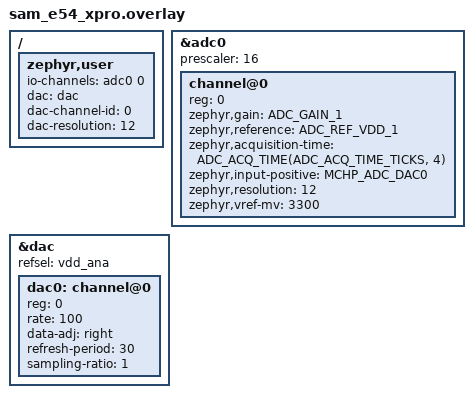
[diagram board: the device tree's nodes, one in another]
/*
 * Copyright (c) 2026 Microchip Technology Inc.
 *
 * SPDX-License-Identifier: Apache-2.0
 */

/* DAC0 internally connected to ADC channel 30 */

/ {
	zephyr,user {
		io-channels = <&adc0 0>;
		dac = <&dac>;
		dac-channel-id = <0>;
		dac-resolution = <12>;
	};
};

&adc0 {
	#address-cells = <1>;
	#size-cells = <0>;
	prescaler = <16>;
	status = "okay";

	channel@0 {
		reg = <0>;
		zephyr,gain = "ADC_GAIN_1";
		zephyr,reference = "ADC_REF_VDD_1";
		zephyr,acquisition-time = <ADC_ACQ_TIME(ADC_ACQ_TIME_TICKS, 4)>;
		zephyr,input-positive = <MCHP_ADC_DAC0>;
		zephyr,resolution = <12>;
		zephyr,vref-mv = <3300>;
	};
};

&dac {
	refsel = "vdd_ana";
	#address-cells = <1>;
	#size-cells = <0>;
	status = "okay";

	dac0: channel@0 {
		reg = <0>;
		rate = <100>;
		data-adj = "right";
		refresh-period = <30>;
		sampling-ratio = <1>;
	};
};
